# ET6801 register map
Vendor: ETMCU Inc.; File version: v0.0.1
CPU: CM7 r2p1, little endian, MPU, FPU, I-cache, D-cache, ITCM, DTCM, 4 interrupt priority bits
Registers are 32-bit, read-write, reset 0x0 unless marked. A register's access mark holds for its fields unless they carry their own. Offsets are from the block's base; [hi:lo] are bit positions; lines under a group give offsets from that group; {n}, {i} and the like mark numbered series.

## LIN0 — Provide an overview of the purpose and functionality of the peripheral: lin
Base 0x40510000
Same registers: LIN1 0x40511000
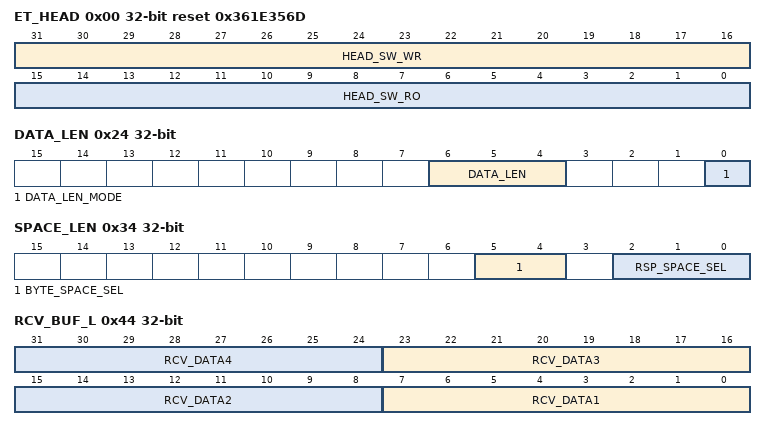
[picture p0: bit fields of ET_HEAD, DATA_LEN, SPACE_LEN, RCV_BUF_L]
0x00 ET_HEAD reset 0x361E356D
  [31:16] HEAD_SW_WR — 软件测试读写寄存器，硬件无访问
  [15:0] HEAD_SW_RO ro — 软件只读上报寄存器，硬件无访问，LIN ASICII码的CRC表示
0x04 EN
  [0] LIN_EN — 软件在初始化完成后进行使能lin_en，lin控制器进入正常工作状态，直到复位或者从睡眠状态唤醒后，硬件自动清零lin_en信号。 0：LIN控制器关闭 1：LIN控制器使能
0x08 MODE
  [0] MODE — LIN控制器主节点/从节点控制位，lin_en使能后不可更改配置 0：从节点 1：主节点
0x0C HEAD_REQ
  [0] HEAD_REQ — 在LIN控制器作为主节点（lin_mode=1）时，LIN控制器接收到软件配置的head_req帧头发送的请求，master task按照lin协议要求发送帧头。当硬件帧头发送完成后，硬件自动清零head_req。 0：不发送帧头 1：帧头发送请求
0x10 RSP_REQ
  [0] RSP_REQ — 在LIN控制器作为从节点（lin_mode=0）时，LIN控制器在接收到完整帧头后，发起pid_done信号： 软件收到该信号后，判断接收的ID是否需要slave响应，如果需要响应，则发送rsp_req响应请求，同时更新对应ID需要传输的data_len、chksum_mode、rsp_transmit等信息。响应完成，硬件自动清0。 在ID过滤使能时，软件不需要配置rsp_req，硬件会自动匹配帧ID并更新帧ID对应的信息。 0：不响应帧ID 1：响应帧ID
0x14 RSP_TRANSMIT
  [0] RSP_TRANSMIT — 软件响应情况下，帧响应的接收/发送控制位，在rsp_req为1时有效，在ID过滤使能时，使用过滤器的配置信息。 0：接收 1：发送
0x18 AUTOBAUD_EN reset 0x1
  [0] AUTOBAUD_EN — LIN控制器从任务自动波特率使能信号，在LIN控制器使能后不可配，默认启用波特率自动同步。 0：禁用波特率自同步功能 1：启用波特率自同步功能
0x1C AUTOBAUD_REQ
  [0] AUTOBAUD_REQ — LIN控制器从节点自动波特率同步检测请求信号，默认是请求同步，便于在接收到LIN帧的不同状态下均可以通过同步间隔场和同步场的监测和同步，实现对LIN控制器的正常通信。硬件在同步成功后清零。
0x20 AUTOBAUD_VAL reset 0x4E2
  [15:0] BAUD_VAL — 波特率计数值，按计数时钟25M计算可得： 默认波特率20kbps：25M/20K=1250（0x4e2） 最大计数值为波特率1kbps：25M/1k=25000（0x61a8）
0x24 DATA_LEN
  [6:4] DATA_LEN — 发送和接收的字节长度配置，在ID过滤使能时，过滤ID与接收ID匹配时更新。
  [0] DATA_LEN_MODE — 传输数据长度的解析模式，发送接收数据的字节长度（0~8字节），在ID过滤使能时，过滤ID与接收ID匹配时更新。 0：使用寄存器data_len的字节长度配置 1：解析ID中的字节长度 解析规则如下： =11 8byte
0x28 MST_SYNCBREAK_SEL
  [3:0] MST_SYNCBREAK_SEL — master task发送的同步间隔场长度，软件配置 0000：13 bit 0001：14 bit 0010：15 bit 0011：16 bit ....... 1100：25 bit 1101：26 bit 1110：27 bit 1111：28 bit
0x2C SLV_SYNCBREAK_SEL reset 0x1
  [0] SLV_SYNCBREAK_SEL — slave task接收到的同步间隔场长度，软件配置 0：检测至少10 bit同步间隔场 1：检测至少11 bit同步间隔场
0x30 DELIMITER_LEN
  [0] DEL_LEN_SEL — 同步间隔场界定符长度，软件配置 0：1 bit 1：2 bit
0x34 SPACE_LEN
  [5:4] BYTE_SPACE_SEL — 在帧字节域发送时，需要满足byte_space_len的长度间隔 00：无间隔 01: 1bit间隔 10：2bit间隔 11: 4 bit间隔
  [2:0] RSP_SPACE_SEL — slave task在发送响应时，需要满足rsp_space_len的长度间隔再发送数据，以保证其他节点有足够时间处理数据 000：无间隔 001: 1bit间隔 010: 2 bit间隔 011: 4 bit间隔 100：8bit间隔 101: 16 bit间隔 110: 18 bit间隔 111: 24 bit间隔 注意：帧响应最大为1.4倍标准帧长，故需要满足如下约束： N* byte_space_len+ rsp_space_len<=(N+1)*10*0.4
0x38 RX_ID ro
  [5:0] RX_ID — 6 bit接收的帧id寄存器，硬件写入，在ID过滤使能时，过滤ID与接收ID匹配时更新。
0x3C TX_ID
  [5:0] TX_ID — 6 bit发送的帧id寄存器，软件写入
0x40 CHKSUM
  [0] CHECKSUM_MODE — 校验类型配置，软件配置。1.3协议版本只支持经典校验和，2.0以上版本支持增强校验和。注意：帧ID为0x3c和0x3d的诊断帧只能用经典校验和。在ID过滤使能时，过滤ID与接收ID匹配时更新。 0：经典校验和 1：增强校验和
0x44 RCV_BUF_L ro
  [8n-1:8n-8] RCV_DATA{n} (n=1..4) — 数据场第{n}个字节数据
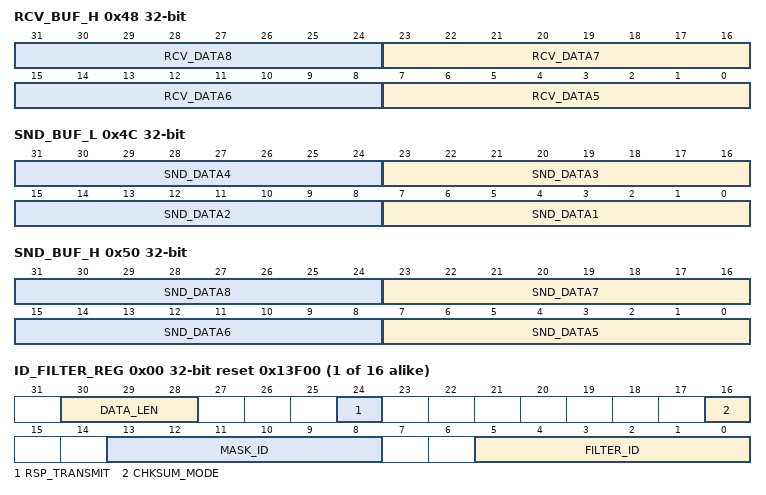
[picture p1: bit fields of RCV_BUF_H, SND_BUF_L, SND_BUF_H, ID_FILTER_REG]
0x48 RCV_BUF_H ro
  [8n-33:8n-40] RCV_DATA{n} (n=5..8) — 数据场第{n}个字节数据
0x4C SND_BUF_L
  [8n-1:8n-8] SND_DATA{n} (n=1..4) — 数据场第{n}个字节数据
0x50 SND_BUF_H
  [8n-33:8n-40] SND_DATA{n} (n=5..8) — 数据场第{n}个字节数据
0x54 ID_FILTER_BYPASS
  [0] ID_FILTER_BYPASS — ID过滤bypass使能寄存器 0：启用id过滤功能，使用当前软件配置参数 1：禁用id过滤功能，使用匹配id的预配置参数
0x58 ID_FILTER_EN
  [15:0] ID_FILTER_EN — ID过滤器使能，对应16个过滤器的使能配置 id_filter_en[x]=0表示禁用第x个ID过滤器 id_filter_en[x]=1表示启用第x个ID过滤器 注意：当处于掩码模式下的过滤器，始终处于激活状态，可用于对应ID过滤器的掩码运算操作。
0x5C ID_FILTER_MASK_EN
  [15:0] ID_FILTER_MASK_EN — 对应ID过滤列表中的ID的掩码模式使能。 id_filter_mask_en[0]=0，表示ID_FILTER_REG0.filter_id是列表模式，需要slave接收到的ID与ID_FILTER_REG0.filter_id中的预设ID完全一致，才能通过过滤器。 id_filter_mask_en[0]=1，表示ID_FILTER_REG0.filter_id是掩码模式，ID_FILTER_REG0.mask_id中的ID是ID_FILTER_REG0.filter_id的掩码ID，需要slave接收到的ID与ID_FILTER_REG0.mask_id中的掩码ID逻辑与后再比较与预设ID是否一致。
0x60 ID_FILTER_MATCH ro
  [4:0] ID_FILTER_MATCH — ID匹配的过滤器上报，便于软件查询是哪个过滤器匹配成功。一共16个过滤器，比如，当过滤器1匹配上，id_filter_match=1，表示第一个过滤器匹配成功。 注意：id_filter_match=0，表示所有ID过滤器中的ID都没有匹配成功。
{0x64+4i} ID_FILTER_REG[{i}] (i=0..15) group — LIN_ID_FILTER_REG
  0x00 ID_FILTER_REG reset 0x13F00
    [30:28] DATA_LEN — 发送和接收的字节长度配置
    [24] RSP_TRANSMIT — 响应的接收/发送控制位，在rsp_req为1时有效，在ID过滤使能时，过滤ID与接收ID匹配时更新。
    [16] CHKSUM_MODE — 校验类型配置，软件配置。1.3协议版本只支持经典校验和，2.0以上版本支持增强校验和。注意：帧ID为0x3c和0x3d的诊断帧只能用经典校验和。 0：经典校验和 1：增强校验和
    [13:8] MASK_ID — 过滤列表中的掩码ID，默认为列表模式
    [5:0] FILTER_ID — slave中ID过滤列表中的帧ID
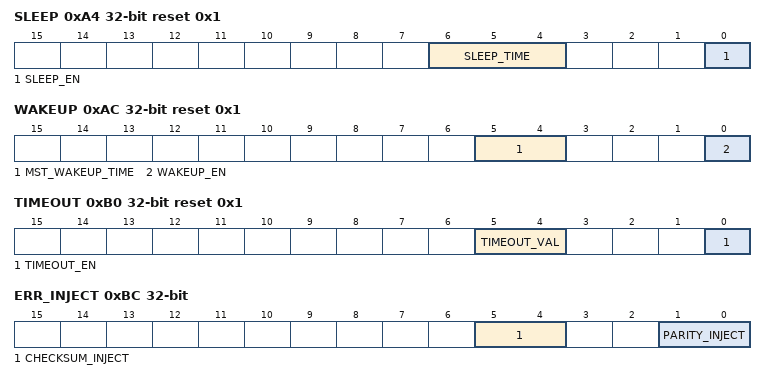
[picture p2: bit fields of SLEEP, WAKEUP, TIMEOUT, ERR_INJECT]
0xA4 SLEEP reset 0x1
  [6:4] SLEEP_TIME — 总线进入睡眠状态的静默时间配置（协议标准4~10s），硬件检测到rx管脚高电平时间达到睡眠静默时间，产生sleep_flag中断上报至软件 000-4s;001-5s.....110-10s
  [0] SLEEP_EN — 接收到有效sleep_flag后，软件配置sleep_en决定睡眠指令是否有效 0：无效睡眠指令 1：有效睡眠指令
0xA8 WAKEUP_REQ
  [0] WAKEUP_REQ — 软件配置wakeup_req=1，LIN控制器发送协议标准的唤醒信号
0xAC WAKEUP reset 0x1
  [5:4] MST_WAKEUP_TIME — 发起唤醒信号时间配置，总线检测到wakeup_time时间的唤醒信号，置起wakeup_flag中断，上报软件。 00-250us; 01-500us; 10-2ms; 11-5ms
  [0] WAKEUP_EN — 接收到或者发出有效wakeup_flag后，软件配置wakeup_en决定唤醒请求是否有效 0：无效唤醒请求 1：有效唤醒请求
0xB0 TIMEOUT reset 0x1
  [5:4] TIMEOUT_VAL — 超时时间配置，对于主节点超时发生在没有slave响应、slave响应太迟或者响应在最大帧时隙未完成等情况下。对于从节点超时发生在接收帧头后且该响应时，软件长时间未置起rsp_req，或者slave发出有效唤醒信号后，在150ms内未接收到主节点的帧头。 00-100 bit; 01-120 bit; 10-150 bit; 11-200 bit
  [0] TIMEOUT_EN — 超时检测使能 0：禁用超时检测功能 1：启用超时检测功能
0xB4 LOOP_TEST
  [0] LOOP_TEST_EN — 环回测试使能，IP内部环回(rx,tx短接)，注意此时gpio的rx、tx均需要断开(OEN不使能)，为了不影响总线的正常通信。 0：禁用环回测试功能 1：使能环回测试功能
0xB8 LP_BYPASS
  [0] LP_BYPASS — LIN控制器低功耗bypass功能 0：启用低功耗功能 1：bypass低功耗功能
0xBC ERR_INJECT
  [5:4] CHECKSUM_INJECT — checksum校验和注错 bit4代表接收checksum注错，bit5代表发送checksum注错 0：不注错 1：1bit注错
  [1:0] PARITY_INJECT — pid奇偶校验注错 bit0代表接收parity注错，bit1代表发送parity注错 0：不注错 1：1bit注错
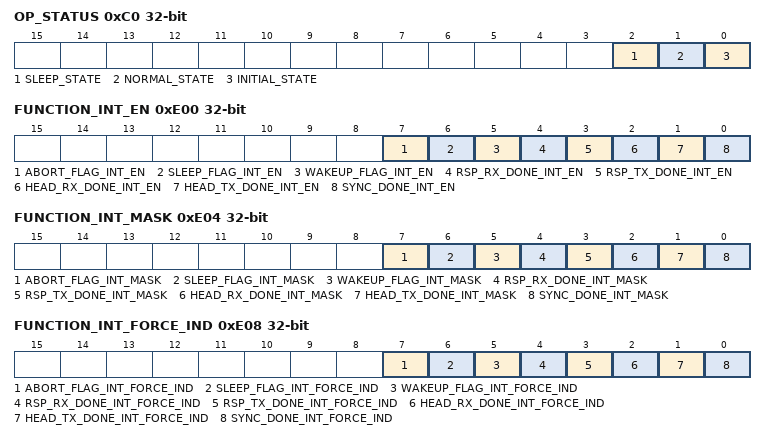
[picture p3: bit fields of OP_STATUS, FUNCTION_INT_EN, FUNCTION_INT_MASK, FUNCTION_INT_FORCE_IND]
0xC0 OP_STATUS ro
  [2] SLEEP_STATE — 睡眠状态
  [1] NORMAL_STATE — 正常工作状态
  [0] INITIAL_STATE — 初始化状态
0xC4 TRANS_BYTE_RPT ro
  [3:0] TRANS_BYTE_RPT — slave响应中字节传输计数值上报
0xE00 FUNCTION_INT_EN
  [7] ABORT_FLAG_INT_EN — 帧传输中止信号中断使能
  [6] SLEEP_FLAG_INT_EN — 睡眠信号中断使能
  [5] WAKEUP_FLAG_INT_EN — 唤醒信号中断使能
  [4] RSP_RX_DONE_INT_EN — 帧响应接收完成中断使能
  [3] RSP_TX_DONE_INT_EN — 帧响应发送完成中断使能
  [2] HEAD_RX_DONE_INT_EN — slave帧头接收完成中断使能
  [1] HEAD_TX_DONE_INT_EN — master帧头发送完成中断使能
  [0] SYNC_DONE_INT_EN — slave同步完成中断使能
0xE04 FUNCTION_INT_MASK
  [7] ABORT_FLAG_INT_MASK — 帧传输中止信号中断屏蔽
  [6] SLEEP_FLAG_INT_MASK — 睡眠信号中断屏蔽
  [5] WAKEUP_FLAG_INT_MASK — 唤醒信号中断屏蔽
  [4] RSP_RX_DONE_INT_MASK — 帧响应接收完成中断屏蔽
  [3] RSP_TX_DONE_INT_MASK — 帧响应发送完成中断屏蔽
  [2] HEAD_RX_DONE_INT_MASK — slave帧头接收完成中断屏蔽
  [1] HEAD_TX_DONE_INT_MASK — master帧头发送完成中断屏蔽
  [0] SYNC_DONE_INT_MASK — slave同步完成中断屏蔽
0xE08 FUNCTION_INT_FORCE_IND
  [7] ABORT_FLAG_INT_FORCE_IND — 帧传输中止信号强制中断
  [6] SLEEP_FLAG_INT_FORCE_IND — 睡眠信号强制中断
  [5] WAKEUP_FLAG_INT_FORCE_IND — 唤醒信号强制中断
  [4] RSP_RX_DONE_INT_FORCE_IND — 帧响应接收完成强制中断
  [3] RSP_TX_DONE_INT_FORCE_IND — 帧响应发送完成强制中断
  [2] HEAD_RX_DONE_INT_FORCE_IND — slave帧头接收完成强制中断
  [1] HEAD_TX_DONE_INT_FORCE_IND — master帧头发送完成强制中断
  [0] SYNC_DONE_INT_FORCE_IND — slave同步完成强制中断
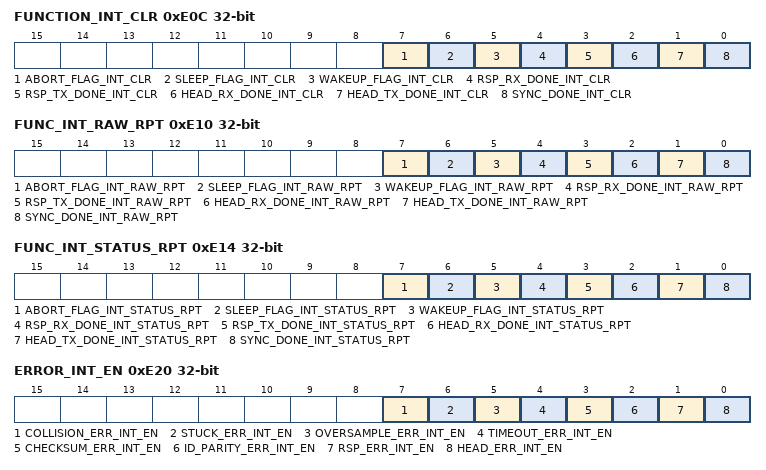
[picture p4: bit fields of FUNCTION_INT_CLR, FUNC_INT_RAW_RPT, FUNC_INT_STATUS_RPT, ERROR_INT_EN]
0xE0C FUNCTION_INT_CLR
  [7] ABORT_FLAG_INT_CLR — 帧传输中止信号中断清除
  [6] SLEEP_FLAG_INT_CLR — 睡眠信号中断清除
  [5] WAKEUP_FLAG_INT_CLR — 唤醒信号中断清除
  [4] RSP_RX_DONE_INT_CLR — 帧响应接收完成中断清除
  [3] RSP_TX_DONE_INT_CLR — 帧响应发送完成中断清除
  [2] HEAD_RX_DONE_INT_CLR — slave帧头接收完成中断清除
  [1] HEAD_TX_DONE_INT_CLR — master帧头发送完成中断清除
  [0] SYNC_DONE_INT_CLR — slave同步完成中断清除
0xE10 FUNC_INT_RAW_RPT ro
  [7] ABORT_FLAG_INT_RAW_RPT — 帧传输中止信号raw中断上报
  [6] SLEEP_FLAG_INT_RAW_RPT — 睡眠信号raw中断上报
  [5] WAKEUP_FLAG_INT_RAW_RPT — 唤醒信号raw中断上报
  [4] RSP_RX_DONE_INT_RAW_RPT — 帧响应接收完成raw中断上报
  [3] RSP_TX_DONE_INT_RAW_RPT — 帧响应发送完成raw中断上报
  [2] HEAD_RX_DONE_INT_RAW_RPT — slave帧头接收完成raw中断上报
  [1] HEAD_TX_DONE_INT_RAW_RPT — master帧头发送完成raw中断上报
  [0] SYNC_DONE_INT_RAW_RPT — slave同步完成raw中断上报
0xE14 FUNC_INT_STATUS_RPT ro
  [7] ABORT_FLAG_INT_STATUS_RPT — 帧传输中止信号屏蔽status中断上报
  [6] SLEEP_FLAG_INT_STATUS_RPT — 睡眠信号屏蔽status中断上报
  [5] WAKEUP_FLAG_INT_STATUS_RPT — 唤醒信号屏蔽status中断上报
  [4] RSP_RX_DONE_INT_STATUS_RPT — 帧响应接收完成屏蔽status中断上报
  [3] RSP_TX_DONE_INT_STATUS_RPT — 帧响应发送完成屏蔽status中断上报
  [2] HEAD_RX_DONE_INT_STATUS_RPT — slave帧头接收完成屏蔽status中断上报
  [1] HEAD_TX_DONE_INT_STATUS_RPT — master帧头发送完成屏蔽status中断上报
  [0] SYNC_DONE_INT_STATUS_RPT — slave同步完成屏蔽status中断上报
0xE20 ERROR_INT_EN
  [7] COLLISION_ERR_INT_EN — 冲突检测错误中断使能
  [6] STUCK_ERR_INT_EN — 钳位错误中断使能
  [5] OVERSAMPLE_ERR_INT_EN — 过采样错误中断使能
  [4] TIMEOUT_ERR_INT_EN — 出现响应超时错误中断使能
  [3] CHECKSUM_ERR_INT_EN — 响应中校验和检测错误中断使能
  [2] ID_PARITY_ERR_INT_EN — 帧头中id奇偶检验错误中断使能
  [1] RSP_ERR_INT_EN — 响应检测错误中断使能
  [0] HEAD_ERR_INT_EN — 帧头检测错误中断使能
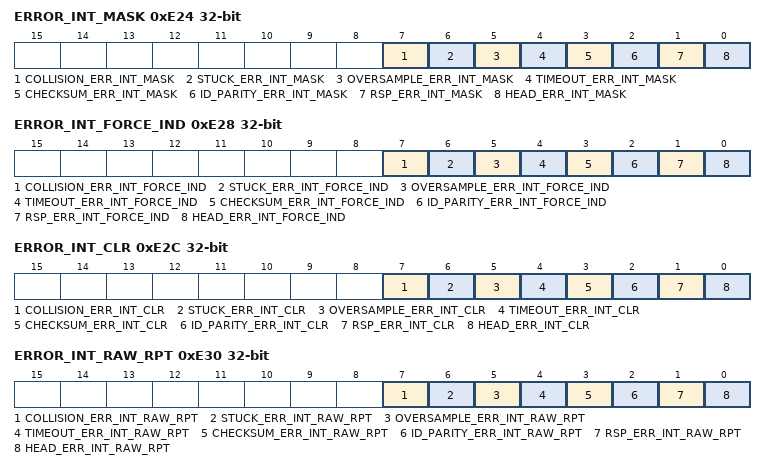
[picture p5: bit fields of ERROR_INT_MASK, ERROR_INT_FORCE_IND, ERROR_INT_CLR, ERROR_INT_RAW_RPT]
0xE24 ERROR_INT_MASK
  [7] COLLISION_ERR_INT_MASK — 冲突检测错误中断屏蔽
  [6] STUCK_ERR_INT_MASK — 钳位错误中断屏蔽
  [5] OVERSAMPLE_ERR_INT_MASK — 过采样错误中断屏蔽
  [4] TIMEOUT_ERR_INT_MASK — 出现响应超时错误中断屏蔽
  [3] CHECKSUM_ERR_INT_MASK — 响应中校验和检测错误中断屏蔽
  [2] ID_PARITY_ERR_INT_MASK — 帧头中id奇偶检验错误中断屏蔽
  [1] RSP_ERR_INT_MASK — 响应检测错误中断屏蔽
  [0] HEAD_ERR_INT_MASK — 帧头检测错误中断屏蔽
0xE28 ERROR_INT_FORCE_IND
  [7] COLLISION_ERR_INT_FORCE_IND — 冲突检测错误强制中断
  [6] STUCK_ERR_INT_FORCE_IND — 钳位错误强制中断
  [5] OVERSAMPLE_ERR_INT_FORCE_IND — 过采样错误强制中断
  [4] TIMEOUT_ERR_INT_FORCE_IND — 出现响应超时错误强制中断
  [3] CHECKSUM_ERR_INT_FORCE_IND — 响应中校验和检测错误强制中断
  [2] ID_PARITY_ERR_INT_FORCE_IND — 帧头中id奇偶检验错误强制中断
  [1] RSP_ERR_INT_FORCE_IND — 响应检测错误强制中断
  [0] HEAD_ERR_INT_FORCE_IND — 帧头检测错误强制中断
0xE2C ERROR_INT_CLR
  [7] COLLISION_ERR_INT_CLR — 冲突检测错误中断清除
  [6] STUCK_ERR_INT_CLR — 钳位中断错误清除，出现长时间没有显性和隐形电平之间的切换
  [5] OVERSAMPLE_ERR_INT_CLR — 过采样中断错误清除
  [4] TIMEOUT_ERR_INT_CLR — 出现响应超时中断错误清除
  [3] CHECKSUM_ERR_INT_CLR — 响应中校验和检测中断错误清除
  [2] ID_PARITY_ERR_INT_CLR — 帧头中id奇偶检验中断错误清除
  [1] RSP_ERR_INT_CLR — 响应检测中断错误清除
  [0] HEAD_ERR_INT_CLR — 帧头检测中断错误清除
0xE30 ERROR_INT_RAW_RPT ro
  [7] COLLISION_ERR_INT_RAW_RPT — 冲突检测错误原始中断上报
  [6] STUCK_ERR_INT_RAW_RPT — 钳位原始中断错误上报，出现长时间没有显性和隐形电平之间的切换
  [5] OVERSAMPLE_ERR_INT_RAW_RPT — 过采样原始中断错误上报
  [4] TIMEOUT_ERR_INT_RAW_RPT — 出现响应超时错误或者初始化后100ms内未检测到帧头
  [3] CHECKSUM_ERR_INT_RAW_RPT — 响应中校验和检测原始中断错误上报
  [2] ID_PARITY_ERR_INT_RAW_RPT — 帧头中id奇偶检验原始中断错误上报
  [1] RSP_ERR_INT_RAW_RPT — 响应检测原始中断错误上报，主要是停止位检测
  [0] HEAD_ERR_INT_RAW_RPT — 帧头检测原始中断错误上报
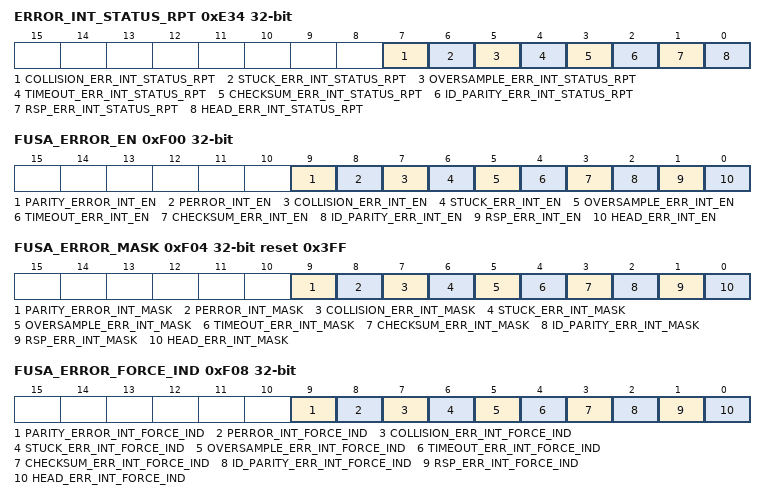
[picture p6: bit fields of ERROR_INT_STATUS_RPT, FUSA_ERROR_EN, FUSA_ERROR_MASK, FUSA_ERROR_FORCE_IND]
0xE34 ERROR_INT_STATUS_RPT ro
  [7] COLLISION_ERR_INT_STATUS_RPT — 冲突检测错误屏蔽状态中断上报
  [6] STUCK_ERR_INT_STATUS_RPT — 钳位屏蔽状态错误上报，出现长时间没有显性和隐形电平之间的切换
  [5] OVERSAMPLE_ERR_INT_STATUS_RPT — 过采样屏蔽状态错误上报
  [4] TIMEOUT_ERR_INT_STATUS_RPT — 出现响应超时错误或者初始化后100ms内未检测到帧头
  [3] CHECKSUM_ERR_INT_STATUS_RPT — 响应中校验和检测屏蔽状态错误上报
  [2] ID_PARITY_ERR_INT_STATUS_RPT — 帧头中id奇偶检验屏蔽状态错误上报
  [1] RSP_ERR_INT_STATUS_RPT — 响应检测屏蔽状态错误上报，主要是停止位检测
  [0] HEAD_ERR_INT_STATUS_RPT — 帧头检测屏蔽状态错误上报
0xF00 FUSA_ERROR_EN
  [9] PARITY_ERROR_INT_EN — IDS模块发生奇偶校验错误中断使能
  [8] PERROR_INT_EN — 总线访问权限错误中断使能
  [7] COLLISION_ERR_INT_EN — 冲突检测错误中断使能
  [6] STUCK_ERR_INT_EN — 钳位错误中断使能
  [5] OVERSAMPLE_ERR_INT_EN — 过采样错误中断使能
  [4] TIMEOUT_ERR_INT_EN — 出现响应超时错误中断使能
  [3] CHECKSUM_ERR_INT_EN — 响应中校验和检测错误中断使能
  [2] ID_PARITY_ERR_INT_EN — 帧头中id奇偶检验错误中断使能
  [1] RSP_ERR_INT_EN — 响应检测错误中断使能
  [0] HEAD_ERR_INT_EN — 帧头检测错误中断使能
0xF04 FUSA_ERROR_MASK reset 0x3FF
  [9] PARITY_ERROR_INT_MASK — IDS模块发生奇偶校验错误中断屏蔽
  [8] PERROR_INT_MASK — 总线访问权限错误中断屏蔽
  [7] COLLISION_ERR_INT_MASK — 冲突检测错误中断屏蔽
  [6] STUCK_ERR_INT_MASK — 钳位错误中断屏蔽
  [5] OVERSAMPLE_ERR_INT_MASK — 过采样错误中断屏蔽
  [4] TIMEOUT_ERR_INT_MASK — 出现响应超时错误中断屏蔽
  [3] CHECKSUM_ERR_INT_MASK — 响应中校验和检测错误中断屏蔽
  [2] ID_PARITY_ERR_INT_MASK — 帧头中id奇偶检验错误中断屏蔽
  [1] RSP_ERR_INT_MASK — 响应检测错误中断屏蔽
  [0] HEAD_ERR_INT_MASK — 帧头检测错误中断屏蔽
0xF08 FUSA_ERROR_FORCE_IND
  [9] PARITY_ERROR_INT_FORCE_IND — IDS模块发生奇偶校验错误强制中断
  [8] PERROR_INT_FORCE_IND — 总线访问权限错误强制中断
  [7] COLLISION_ERR_INT_FORCE_IND — 冲突检测错误强制中断
  [6] STUCK_ERR_INT_FORCE_IND — 钳位错误强制中断
  [5] OVERSAMPLE_ERR_INT_FORCE_IND — 过采样错误强制中断
  [4] TIMEOUT_ERR_INT_FORCE_IND — 出现响应超时错误强制中断
  [3] CHECKSUM_ERR_INT_FORCE_IND — 响应中校验和检测错误强制中断
  [2] ID_PARITY_ERR_INT_FORCE_IND — 帧头中id奇偶检验错误强制中断
  [1] RSP_ERR_INT_FORCE_IND — 响应检测错误强制中断
  [0] HEAD_ERR_INT_FORCE_IND — 帧头检测错误强制中断
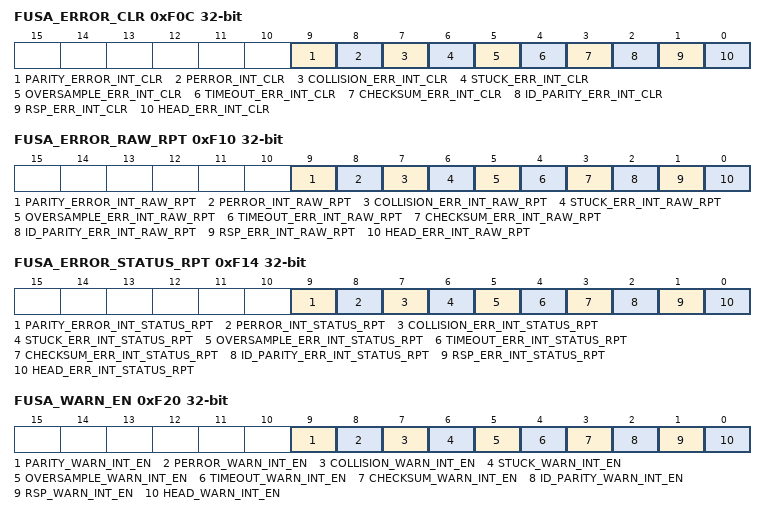
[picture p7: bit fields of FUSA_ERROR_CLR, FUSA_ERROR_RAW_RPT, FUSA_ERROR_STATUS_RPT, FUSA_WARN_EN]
0xF0C FUSA_ERROR_CLR
  [9] PARITY_ERROR_INT_CLR — IDS模块发生奇偶校验错误清除
  [8] PERROR_INT_CLR — 总线访问权限错误清除
  [7] COLLISION_ERR_INT_CLR — 冲突检测错误清除
  [6] STUCK_ERR_INT_CLR — 钳位错误清除
  [5] OVERSAMPLE_ERR_INT_CLR — 过采样错误清除
  [4] TIMEOUT_ERR_INT_CLR — 出现响应超时错误清除
  [3] CHECKSUM_ERR_INT_CLR — 响应中校验和检测错误清除
  [2] ID_PARITY_ERR_INT_CLR — 帧头中id奇偶检验错误清除
  [1] RSP_ERR_INT_CLR — 响应检测错误清除
  [0] HEAD_ERR_INT_CLR — 帧头检测错误清除
0xF10 FUSA_ERROR_RAW_RPT ro
  [9] PARITY_ERROR_INT_RAW_RPT — IDS模块发生奇偶校验错误原始中断上报
  [8] PERROR_INT_RAW_RPT — 总线访问权限错误原始中断上报
  [7] COLLISION_ERR_INT_RAW_RPT — 冲突检测错误原始中断上报
  [6] STUCK_ERR_INT_RAW_RPT — 钳位错误原始中断上报
  [5] OVERSAMPLE_ERR_INT_RAW_RPT — 过采样错误原始中断上报
  [4] TIMEOUT_ERR_INT_RAW_RPT — 出现响应超时错误原始中断上报
  [3] CHECKSUM_ERR_INT_RAW_RPT — 响应中校验和检测错误原始中断上报
  [2] ID_PARITY_ERR_INT_RAW_RPT — 帧头中id奇偶检验错误原始中断上报
  [1] RSP_ERR_INT_RAW_RPT — 响应检测错误原始中断上报
  [0] HEAD_ERR_INT_RAW_RPT — 帧头检测错误原始中断上报
0xF14 FUSA_ERROR_STATUS_RPT ro
  [9] PARITY_ERROR_INT_STATUS_RPT — IDS模块发生奇偶校验错误屏蔽状态上报
  [8] PERROR_INT_STATUS_RPT — 总线访问权限错误屏蔽状态上报
  [7] COLLISION_ERR_INT_STATUS_RPT — 冲突检测错误屏蔽状态上报
  [6] STUCK_ERR_INT_STATUS_RPT — 钳位错误屏蔽状态上报
  [5] OVERSAMPLE_ERR_INT_STATUS_RPT — 过采样错误屏蔽状态上报
  [4] TIMEOUT_ERR_INT_STATUS_RPT — 出现响应超时错误屏蔽状态上报
  [3] CHECKSUM_ERR_INT_STATUS_RPT — 响应中校验和检测错误屏蔽状态上报
  [2] ID_PARITY_ERR_INT_STATUS_RPT — 帧头中id奇偶检验错误屏蔽状态上报
  [1] RSP_ERR_INT_STATUS_RPT — 响应检测错误屏蔽状态上报
  [0] HEAD_ERR_INT_STATUS_RPT — 帧头检测错误屏蔽状态上报
0xF20 FUSA_WARN_EN
  [9] PARITY_WARN_INT_EN — IDS模块发生奇偶校验警告中断使能
  [8] PERROR_WARN_INT_EN — 总线访问权限警告中断使能
  [7] COLLISION_WARN_INT_EN — 冲突检测警告中断使能
  [6] STUCK_WARN_INT_EN — 钳位警告中断使能
  [5] OVERSAMPLE_WARN_INT_EN — 过采样警告中断使能
  [4] TIMEOUT_WARN_INT_EN — 出现响应超时警告中断使能
  [3] CHECKSUM_WARN_INT_EN — 响应中校验和检测警告中断使能
  [2] ID_PARITY_WARN_INT_EN — 帧头中id奇偶检验警告中断使能
  [1] RSP_WARN_INT_EN — 响应检测警告中断使能
  [0] HEAD_WARN_INT_EN — 帧头检测警告中断使能
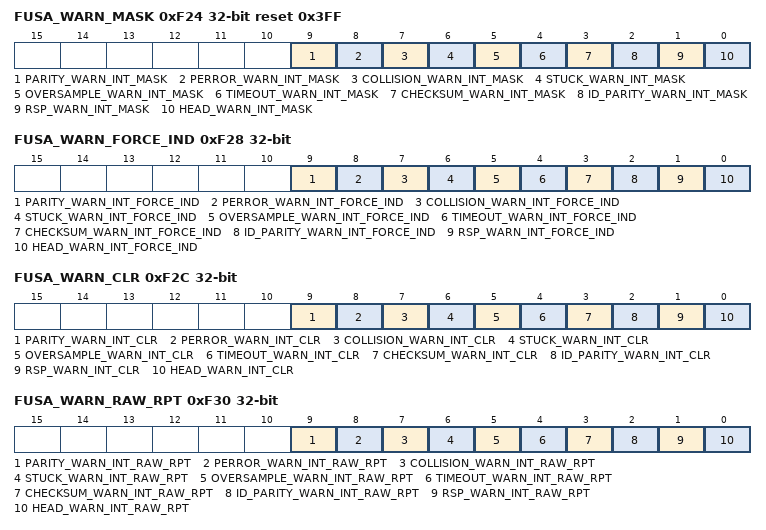
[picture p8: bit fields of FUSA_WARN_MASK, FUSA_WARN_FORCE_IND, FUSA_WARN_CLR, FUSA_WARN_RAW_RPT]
0xF24 FUSA_WARN_MASK reset 0x3FF
  [9] PARITY_WARN_INT_MASK — IDS模块发生奇偶校验警告中断屏蔽
  [8] PERROR_WARN_INT_MASK — 总线访问权限警告中断屏蔽
  [7] COLLISION_WARN_INT_MASK — 冲突检测警告中断屏蔽
  [6] STUCK_WARN_INT_MASK — 钳位警告中断屏蔽
  [5] OVERSAMPLE_WARN_INT_MASK — 过采样警告中断屏蔽
  [4] TIMEOUT_WARN_INT_MASK — 出现响应超时警告中断屏蔽
  [3] CHECKSUM_WARN_INT_MASK — 响应中校验和检测警告中断屏蔽
  [2] ID_PARITY_WARN_INT_MASK — 帧头中id奇偶检验警告中断屏蔽
  [1] RSP_WARN_INT_MASK — 响应检测警告中断屏蔽
  [0] HEAD_WARN_INT_MASK — 帧头检测警告中断屏蔽
0xF28 FUSA_WARN_FORCE_IND
  [9] PARITY_WARN_INT_FORCE_IND — IDS模块发生奇偶校验警告强制中断
  [8] PERROR_WARN_INT_FORCE_IND — 总线访问权限警告强制中断
  [7] COLLISION_WARN_INT_FORCE_IND — 冲突检测警告强制中断
  [6] STUCK_WARN_INT_FORCE_IND — 钳位警告强制中断
  [5] OVERSAMPLE_WARN_INT_FORCE_IND — 过采样警告强制中断
  [4] TIMEOUT_WARN_INT_FORCE_IND — 出现响应超时警告强制中断
  [3] CHECKSUM_WARN_INT_FORCE_IND — 响应中校验和检测警告强制中断
  [2] ID_PARITY_WARN_INT_FORCE_IND — 帧头中id奇偶检验警告强制中断
  [1] RSP_WARN_INT_FORCE_IND — 响应检测警告强制中断
  [0] HEAD_WARN_INT_FORCE_IND — 帧头检测警告强制中断
0xF2C FUSA_WARN_CLR
  [9] PARITY_WARN_INT_CLR — IDS模块发生奇偶校验警告清除
  [8] PERROR_WARN_INT_CLR — 总线访问权限警告清除
  [7] COLLISION_WARN_INT_CLR — 冲突检测警告清除
  [6] STUCK_WARN_INT_CLR — 钳位警告清除
  [5] OVERSAMPLE_WARN_INT_CLR — 过采样警告清除
  [4] TIMEOUT_WARN_INT_CLR — 出现响应超时警告清除
  [3] CHECKSUM_WARN_INT_CLR — 响应中校验和检测警告清除
  [2] ID_PARITY_WARN_INT_CLR — 帧头中id奇偶检验警告清除
  [1] RSP_WARN_INT_CLR — 响应检测警告清除
  [0] HEAD_WARN_INT_CLR — 帧头检测警告清除
0xF30 FUSA_WARN_RAW_RPT ro
  [9] PARITY_WARN_INT_RAW_RPT — IDS模块发生奇偶校验警告原始中断上报
  [8] PERROR_WARN_INT_RAW_RPT — 总线访问权限警告原始中断上报
  [7] COLLISION_WARN_INT_RAW_RPT — 冲突检测警告原始中断上报
  [6] STUCK_WARN_INT_RAW_RPT — 钳位警告原始中断上报
  [5] OVERSAMPLE_WARN_INT_RAW_RPT — 过采样警告原始中断上报
  [4] TIMEOUT_WARN_INT_RAW_RPT — 出现响应超时警告原始中断上报
  [3] CHECKSUM_WARN_INT_RAW_RPT — 响应中校验和检测警告原始中断上报
  [2] ID_PARITY_WARN_INT_RAW_RPT — 帧头中id奇偶检验警告原始中断上报
  [1] RSP_WARN_INT_RAW_RPT — 响应检测警告原始中断上报
  [0] HEAD_WARN_INT_RAW_RPT — 帧头检测警告原始中断上报
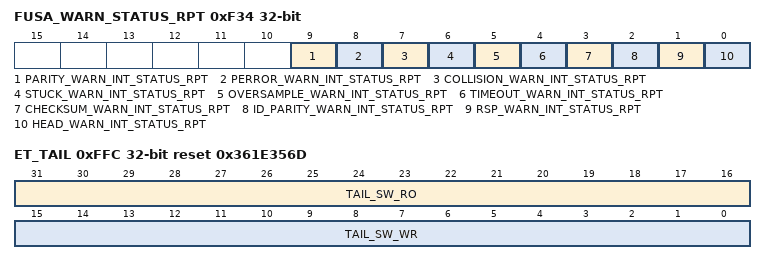
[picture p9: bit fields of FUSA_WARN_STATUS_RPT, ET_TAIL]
0xF34 FUSA_WARN_STATUS_RPT ro
  [9] PARITY_WARN_INT_STATUS_RPT — IDS模块发生奇偶校验警告屏蔽状态上报
  [8] PERROR_WARN_INT_STATUS_RPT — 总线访问权限警告屏蔽状态上报
  [7] COLLISION_WARN_INT_STATUS_RPT — 冲突检测警告屏蔽状态上报
  [6] STUCK_WARN_INT_STATUS_RPT — 钳位警告屏蔽状态上报
  [5] OVERSAMPLE_WARN_INT_STATUS_RPT — 过采样警告屏蔽状态上报
  [4] TIMEOUT_WARN_INT_STATUS_RPT — 出现响应超时警告屏蔽状态上报
  [3] CHECKSUM_WARN_INT_STATUS_RPT — 响应中校验和检测警告屏蔽状态上报
  [2] ID_PARITY_WARN_INT_STATUS_RPT — 帧头中id奇偶检验警告屏蔽状态上报
  [1] RSP_WARN_INT_STATUS_RPT — 响应检测警告屏蔽状态上报
  [0] HEAD_WARN_INT_STATUS_RPT — 帧头检测警告屏蔽状态上报
0xF40 FUSA_PERROR2BUS_ERR
  [0] PERROR2BUS_ERR_EN — 1表示当出现权限访问错误时，返回总线错误 0表示当出现权限访问错误时，不返回总线错误
0xF44 FUSA_MASTER_BITMAP reset 0xFFFFFFFF
  [31:0] MASTER_BITMAP — 基于MASTER ID访问保护配置，1表示该MASTER允许访问，0表示禁止访问 bit0 控制MASTER_ID = 0的MASTER访问权限 bit1 控制MASTER_ID = 1的MASTER访问权限 ... bit31 控制MASTER_ID = 31的MASTER访问权限
0xF48 REG_ERROR_MASTER_ID_RPT ro
  [4:0] REG_ERROR_MASTER_ID — 记录以下几种错误发生时的master ID 1当出现[sv,se,e,mp]权限错误访问错误 2当寄存器出现parity校验错误（如果存在parity校验安全机制） 3当寄存器出现SECDED错误时（如果存在SECDED校验安全机制） 4当寄存器出现CRC错误时（如果存在CRC校验安全机制） 5当寄存器出现TMR错误时（如果存在TMR校验安全机制）
0xFA0 FUSA_PARITY_ERR_INJECT_EN
  [0] FUSA_PARITY_ERR_INJECT_EN — Parity注错测试使能，注错测试时，先设置该bit为1，然后需要软件读取相应的寄存器触发产生Parity错误
0xFFC ET_TAIL reset 0x361E356D
  [31:16] TAIL_SW_RO ro — 软件只读硬件上报寄存器
  [15:0] TAIL_SW_WR — 软件测试读写寄存器，硬件无访问，LIN ASICII码的CRC表示
